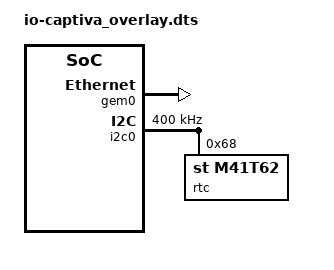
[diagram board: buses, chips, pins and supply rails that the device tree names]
/dts-v1/;
/plugin/;

#include <dt-bindings/input/input.h>
#include <dt-bindings/gpio/gpio.h>
#include <dt-bindings/pinctrl/pinctrl-zynqmp.h>
#include <dt-bindings/phy/phy.h>

&gem0 {
    status = "okay";
};

&gem1 {
    status = "disabled";
};

&gem2 {
    status = "disabled";
};

&gem3 {
    status = "disabled";
};

// disabled zynqmp rtc
&rtc {
    status = "disabled";
};

// enable carrier rtc
&i2c0 {
    status = "okay";
    clock-frequency = <400000>;

    rtc@68 {
        compatible = "st,m41t62";
        reg = <0x68>;
    };
};

